# STC32G144K246 register map
Vendor: STC; File version: 2.0
Registers are 8-bit, read-write, no defined reset value unless marked. A register's access mark holds for its fields unless they carry their own. Offsets are from the block's base; [hi:lo] are bit positions; {n}, {i} and the like mark numbered series.

## HSPWMD — 高速 PWM D 配置；不访问间接窗口
Base 0x007EF974
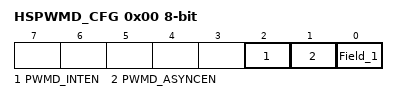
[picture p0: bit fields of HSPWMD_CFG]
0x00 HSPWMD_CFG ro — 高速PWMD配置寄存器
  [2] PWMD_INTEN — 异步模式中断使能位（n=A/B/C/D/E/F）
    0=关闭异步模式下的PWMn 中断。; 1=使能异步模式下的PWMn 中断。
  [1] PWMD_ASYNCEN — 异步控制模式使能位（n=A/B/C/D/E/F）
    0=关闭异步控制。; 1=使能异步控制模式。
  [0] Field_1 — 尚未自动匹配到此字段的独立说明；请查看下方章节说明。

## HSPWME — 高速 PWM E 配置；不访问间接窗口
Base 0x007EF688
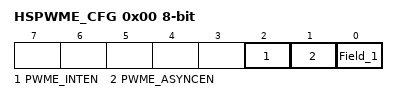
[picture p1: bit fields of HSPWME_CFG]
0x00 HSPWME_CFG ro — 高速PWME配置寄存器
  [2] PWME_INTEN — 异步模式中断使能位（n=A/B/C/D/E/F）
    0=关闭异步模式下的PWMn 中断。; 1=使能异步模式下的PWMn 中断。
  [1] PWME_ASYNCEN — 异步控制模式使能位（n=A/B/C/D/E/F）
    0=关闭异步控制。; 1=使能异步控制模式。
  [0] Field_1 — 尚未自动匹配到此字段的独立说明；请查看下方章节说明。

## HSPWMF — 高速 PWM F 配置；不访问间接窗口
Base 0x007EF68C
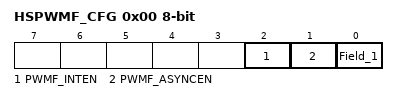
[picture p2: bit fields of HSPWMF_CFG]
0x00 HSPWMF_CFG ro — 高速PWMF配置寄存器
  [2] PWMF_INTEN — 异步模式中断使能位（n=A/B/C/D/E/F）
    0=关闭异步模式下的PWMn 中断。; 1=使能异步模式下的PWMn 中断。
  [1] PWMF_ASYNCEN — 异步控制模式使能位（n=A/B/C/D/E/F）
    0=关闭异步控制。; 1=使能异步控制模式。
  [0] Field_1 — 尚未自动匹配到此字段的独立说明；请查看下方章节说明。

## USB — USB 2.0 FS 直接控制和时钟；端点寄存器为间接索引
Base 0x100000DC
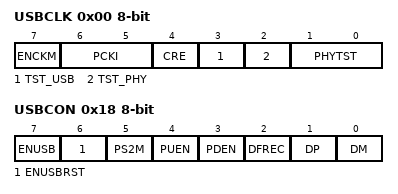
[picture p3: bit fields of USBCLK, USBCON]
0x00 USBCLK ro — USB时钟控制寄存器
  [7] ENCKM — PLL 倍频控制
    0=禁止PLL 倍频; 1=使能PLL 倍频
  [6:5] PCKI — PLL 时钟选择
    0=/1; 1=/2; 2=/4; 3=/8
  [4] CRE — 时钟追频控制位
    0=禁止时钟追频; 1=使能时钟追频
  [3] TST_USB — USB 测试模式
    0=禁止USB 测试模式; 1=使能USB 测试模式
  [2] TST_PHY — PHY 测试模式
    0=禁止PHY 测试模式; 1=使能PHY 测试模式
  [1:0] PHYTST — USB PHY 测试
    0=方式：方式0：正常；DP：x；DM：x; 1=方式：方式1：强制“1”；DP：1；DM：0; 2=方式：方式2：强制“0”；DP：0；DM：1; 3=方式：方式3：强制单端“0”；DP：0；DM：0
0x18 USBCON ro — USB控制寄存器
  [7] ENUSB — USB 功能与USB 时钟控制位
    0=关闭USB 功能与USB 时钟; 1=使能USB 功能与USB 时钟
  [6] ENUSBRST — USB 复位设置控制位
    0=关闭USB 复位设置; 1=使能USB 复位
  [5] PS2M — PS2 mode 功能控制位
    0=关闭PS2 mode 功能; 1=使能PS2 mode 功能
  [4] PUEN — DP/DM 端口上1.5K 上拉电阻控制位
    0=禁止上拉电阻; 1=使能上拉电阻
  [3] PDEN — DP/DM 端口上500K 下拉电阻控制位
    0=禁止下拉电阻; 1=使能下拉电阻
  [2] DFREC — 差分接收状态位（只读）
    0=当前DP/DM 的差分状态为“0”; 1=当前DP/DM 的差分状态为“1”
  [1] DP — D+端口状态（PS2 为0 时只读，PS2 为1 时可读写）
    0=当前D+为逻辑0 电平; 1=当前D+为逻辑1 电平
  [0] DM — D-端口状态（PS2 为0 时只读，PS2 为1 时可读写）
    0=当前D-为逻辑0 电平; 1=当前D-为逻辑1 电平

## TFT — TFT 8080/6800 总线接口控制和状态
Base 0x007EFE50
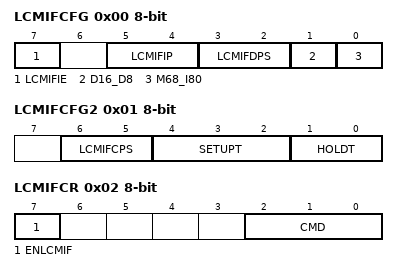
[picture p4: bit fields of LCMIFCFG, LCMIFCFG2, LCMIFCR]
0x00 LCMIFCFG — LCM接口配置寄存器
  [7] LCMIFIE — TFT彩屏接口中断允许位。
    0=禁止TFT 彩屏接口中断; 1=允许TFT 彩屏接口中断
  [5:4] LCMIFIP — TFT彩屏接口中断优先级控制位
    0=最低级（0）; 1=较低级（1）; 2=较高级（2）; 3=最高级（3）
  [3:2] LCMIFDPS — TFT 彩屏接口数据脚选择位
    0=D16_D8：1；数据高字节DAT[15:8]：P2[7:0]；数据低字节DAT[7:0]：P0[7:0]; 1=D16_D8：1；数据高字节DAT[15:8]：P6[7:0]；数据低字节DAT[7:0]：P2[7:0]; 2=D16_D8：1；数据高字节DAT[15:8]：P2[7:0]；数据低字节DAT[7:0]：{P0[7:4],P4[7],P4[6],P4[3],P4[1]}; 3=D16_D8：1；数据高字节DAT[15:8]：P6[7:0]；数据低字节DAT[7:0]：P7[7:0]
  [1] D16_D8 — TFT 彩屏接口数据宽度控制位
    0=8 位数据宽度; 1=16 位数据宽度
  [0] M68_I80 — TFT 彩屏接口模式选择位
    0=i8080 模式; 1=M6800 模式
0x01 LCMIFCFG2 — LCM接口配置寄存器2
  [6:5] LCMIFCPS — TFT 彩屏接口控制脚选择位
    0=RS：P4.5；i8080 的读信号RDM6800 的使能信号E：P4.4；i8080 的写信号WRM6800 的读写信号RW：P4.2; 1=RS：P4.5；i8080 的读信号RDM6800 的使能信号E：P3.7；i8080 的写信号WRM6800 的读写信号RW：P3.6; 2=RS：P4.0；i8080 的读信号RDM6800 的使能信号E：P4.4；i8080 的写信号WRM6800 的读写信号RW：P4.2; 3=RS：P4.0；i8080 的读信号RDM6800 的使能信号E：P3.7；i8080 的写信号WRM6800 的读写信号RW：P3.6
  [4:2] SETUPT — TFT 彩屏接口通讯的数据建立时间控制位（详见后续章节的时序图）
  [1:0] HOLDT — TFT 彩屏接口通讯的数据保持时间控制位（详见后续章节的时序图）
0x02 LCMIFCR ro — LCM接口控制寄存器
  [7] ENLCMIF — TFT 彩屏接口使能控制位
    0=禁止TFT 彩屏接口功能; 1=允许TFT 彩屏接口功能
  [2:0] CMD — TFT 彩屏接口触发命令
    4=写命令; 5=写数据; 6=读命令/状态; 7=读数据
0x03 LCMIFSTA ro — LCM接口状态寄存器
  [0] LCMIFIF — TFT彩屏接口中断请求标志。需要软件清零。
0x06 LCMIFPSCR — LCM接口时钟预分配寄存器
  [7:0] LCMIFPSCR — LCMIF 预分频器。预分频器用于对系统时钟进行预分频，分频后的时钟提供给LCMIF 模块。 LCMIF 时钟频率＝SYSclk /（LCMIFPSCR[7:0]+1）。

## I2S1 — I2S1 音频接口
Base 0x007EFD98
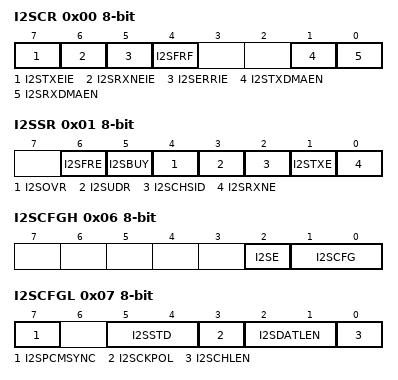
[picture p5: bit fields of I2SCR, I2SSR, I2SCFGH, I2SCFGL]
0x00 I2SCR ro — I2S控制寄存器
  [7] I2STXEIE — I2S发送缓冲区空中断允许位。
    0=禁止I2S 发送缓冲区空中断; 1=允许I2S 发送缓冲区空中断
  [6] I2SRXNEIE — I2S接收缓冲区非空中断允许位。
    0=禁止I2S 接收缓冲区非空中断; 1=允许I2S 接收缓冲区非空中断
  [5] I2SERRIE — I2S错误中断允许位。
    0=禁止I2S 错误中断; 1=允许I2S 错误中断
  [4] I2SFRF — 尚未自动匹配到此字段的独立说明；请查看下方章节说明。
  [1] I2STXDMAEN — 尚未自动匹配到此字段的独立说明；请查看下方章节说明。
  [0] I2SRXDMAEN — 尚未自动匹配到此字段的独立说明；请查看下方章节说明。
0x01 I2SSR ro — I2S状态寄存器
  [6] I2SFRE — 尚未自动匹配到此字段的独立说明；请查看下方章节说明。
  [5] I2SBUY — 尚未自动匹配到此字段的独立说明；请查看下方章节说明。
  [4] I2SOVR — 尚未自动匹配到此字段的独立说明；请查看下方章节说明。
  [3] I2SUDR — 尚未自动匹配到此字段的独立说明；请查看下方章节说明。
  [2] I2SCHSID — 尚未自动匹配到此字段的独立说明；请查看下方章节说明。
  [1] I2STXE — I2S发送缓冲区空中断中断请求标志。不需要软件清零。
  [0] I2SRXNE — I2S接收缓冲区非空中断请求标志。不需要软件清零。
0x06 I2SCFGH — I2S配置寄存器高字节
  [2] I2SE — 尚未自动匹配到此字段的独立说明；请查看下方章节说明。
  [1:0] I2SCFG — 尚未自动匹配到此字段的独立说明；请查看下方章节说明。
0x07 I2SCFGL — I2S配置寄存器低字节
  [7] I2SPCMSYNC — 尚未自动匹配到此字段的独立说明；请查看下方章节说明。
  [5:4] I2SSTD — 尚未自动匹配到此字段的独立说明；请查看下方章节说明。
  [3] I2SCKPOL — 尚未自动匹配到此字段的独立说明；请查看下方章节说明。
  [2:1] I2SDATLEN — 尚未自动匹配到此字段的独立说明；请查看下方章节说明。
  [0] I2SCHLEN — 尚未自动匹配到此字段的独立说明；请查看下方章节说明。
0x08 I2SMD ro
0x09 I2SMCKDIV — I2S时钟分频寄存器
  [7:0] I2SMCKDIV — 尚未自动匹配到此字段的独立说明；请查看下方章节说明。
0xFC I2S_CLKDIV — I2S时钟预分配寄存器
  [7:0] I2S_CLKDIV — 尚未自动匹配到此字段的独立说明；请查看下方章节说明。
